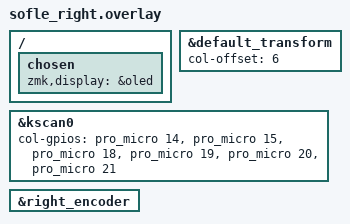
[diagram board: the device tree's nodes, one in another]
#include "sofle.dtsi"

&default_transform {
    col-offset = <6>;
};

&kscan0 {
    col-gpios
        = <&pro_micro 14 GPIO_ACTIVE_HIGH>
        , <&pro_micro 15 GPIO_ACTIVE_HIGH>
        , <&pro_micro 18 GPIO_ACTIVE_HIGH>
        , <&pro_micro 19 GPIO_ACTIVE_HIGH>
        , <&pro_micro 20 GPIO_ACTIVE_HIGH>
        , <&pro_micro 21 GPIO_ACTIVE_HIGH>
        ;
};

&right_encoder {
    status = "okay";
};

/ {
    chosen {
        /* OLED SSD1306 default em 0x3c (alguns módulos usam 0x3d) */
        zmk,display = &oled;
    };
};
